# gpio_ctrl: IP-XACT component
VLNV tenstorrent.com:ocah:gpio_ctrl:1.0

## Address spaces and blocks
gpio_ctrl_mmap.gpio_ctrl: base 'h0, range 'h4, width 32

## Registers
Registers are 32-bit, access per field, reset 0x2 unless marked. A register's access mark holds for its fields unless they carry their own. Offsets are from the block's base; lines under a group give offsets from that group; [hi:lo] are bit positions; {n}, {i} and the like mark numbered series; 'fields as' and 'values as' point back to an identical list; <NAME> marks a mode.

## gpio_ctrl_mmap.gpio_ctrl — Per-pin GPIO pad control registers: drive strength, pull configuration, and strap capture.
Base 0x00000000
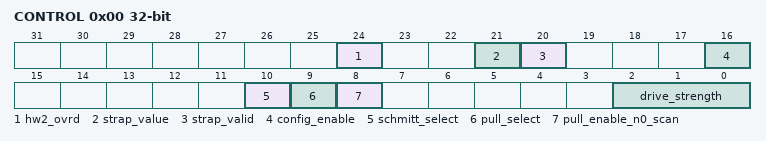
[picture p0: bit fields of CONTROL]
0x00 CONTROL (reset mask 0x1210707)
  [24] hw2_ovrd rw — Setting this register will enable the secondary HW function to override the GPIO enable and data lines.
  [21] strap_value ro — This register holds the captured value that was applied to the pad when reset was de-asserted.
  [20] strap_valid ro — Reflects the INPUT_BY_DEFAULT parameter of the instance: 1 when the pad is an input by default and strap capture is supported, 0 otherwise. Fixed at integration; not a capture-done or reset-done flag.
  [16] config_enable rw — Setting this choosing the register values for PAD settings. This includes pull_enable, pull_select, and schmitt_select
  [10] schmitt_select rw — Register-driven schmitt select.
  [9] pull_select rw — Register-driven pull select - by default we pull down
  [8] pull_enable_n0_scan rw — Register-driven pull enable. Default is disabled
  [2:0] drive_strength rw — Register-driven drive-strength.

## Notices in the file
SPDX-License-Identifier: Apache-2.0
SPDX-FileCopyrightText: 2026 Tenstorrent USA, Inc.
